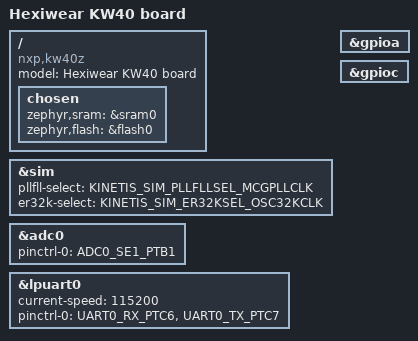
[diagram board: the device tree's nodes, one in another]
/* SPDX-License-Identifier: Apache-2.0 */

/dts-v1/;

#include <nxp/MKW40Z160VHT4.dtsi>

/ {
	model = "Hexiwear KW40 board";
	compatible = "nxp,kw40z", "nxp,mkw40z4";

	chosen {
		zephyr,sram = &sram0;
		zephyr,flash = &flash0;
	};
};

&sim {
	pllfll-select = <KINETIS_SIM_PLLFLLSEL_MCGPLLCLK>;
	er32k-select = <KINETIS_SIM_ER32KSEL_OSC32KCLK>;
};

&adc0 {
	status = "okay";
	pinctrl-0 = <&ADC0_SE1_PTB1>;
	pinctrl-names = "default";
};

&lpuart0 {
	status = "okay";
	current-speed = <115200>;
	pinctrl-0 = <&UART0_RX_PTC6 &UART0_TX_PTC7>;
	pinctrl-names = "default";
};

&gpioa {
	status = "okay";
};

&gpioc {
	status = "okay";
};
